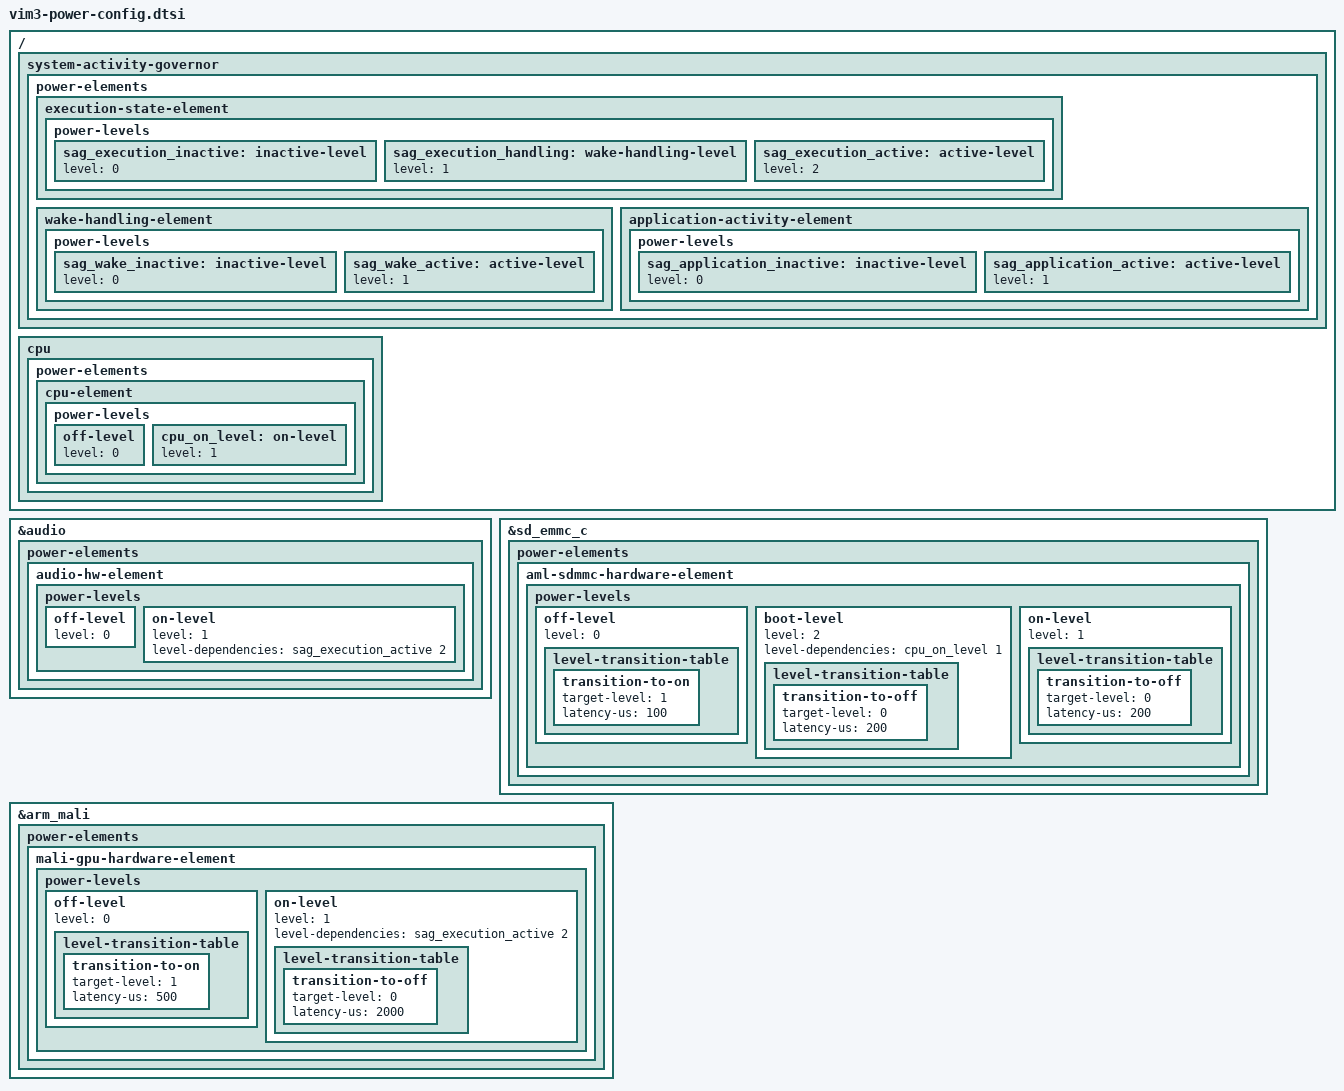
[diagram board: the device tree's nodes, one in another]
// Copyright 2024 The Fuchsia Authors. All rights reserved.
// Use of this source code is governed by a BSD-style license that can be
// found in the LICENSE file.

/dts-v1/;

/include/ "khadas-vim3-board.dtsi"

/ {
	// TODO(https://fxbug.dev/42083285): This has to be kept in sync with
	// sdk/lib/driver/devicetree/visitors/drivers/power/power-element/sag-power-element.yaml and
	// fuchsia.power.system.PowerElements FIDL. For now this needs to be ensured manually.
	// Eventually there will be schema validation and visitor generation based on FIDL.
	system-activity-governor {
		power-elements {
			execution-state-element {
				power-levels {
					sag_execution_inactive: inactive-level {
						level = <0>;
					};
					sag_execution_handling: wake-handling-level {
						level = <1>;
					};
					sag_execution_active: active-level {
						level = <2>;
					};
				};
			};
			wake-handling-element {
				power-levels {
					sag_wake_inactive: inactive-level {
						level = <0>;
					};
					sag_wake_active: active-level {
						level = <1>;
					};
				};
			};
			application-activity-element {
				power-levels {
					sag_application_inactive: inactive-level {
						level = <0>;
					};
					sag_application_active: active-level {
						level = <1>;
					};
				};
			};
		};
	};
	cpu {
		power-elements {
			cpu-element {
				power-levels {
					off-level {
						level = <0>;
					};
					cpu_on_level: on-level {
						level = <1>;
					};
				};
			};
		};
	};
};

&audio {
	power-elements {
		audio-hw-element {
			power-levels {
				off-level {
					level = <0>;
				};
				on-level {
					level = <1>;
					level-dependencies = <&sag_execution_active 2>;
				};
			};
		};
	};
};

&sd_emmc_c {
	power-elements {
		aml-sdmmc-hardware-element {
			power-levels {
				off-level {
					level = <0>;
					level-transition-table {
						transition-to-on {
							target-level = <1>;
							latency-us = <100>;
						};
					};
				};
				boot-level {
					level = <2>;
					level-dependencies = <&cpu_on_level 1>;
					level-transition-table {
						transition-to-off {
							target-level = <0>;
							latency-us = <200>;
						};
					};
        		};
				on-level {
					level = <1>;
					level-transition-table {
						transition-to-off {
							target-level = <0>;
							latency-us = <200>;
						};
					};
				};
			};
		};
	};
};

&arm_mali {
	power-elements {
		mali-gpu-hardware-element {
			power-levels {
				off-level {
					level = <0>;
					level-transition-table {
						transition-to-on {
							target-level = <1>;
							latency-us = <500>;
						};
					};
				};
				on-level {
					level = <1>;
					level-dependencies = <&sag_execution_active 2>;
					level-transition-table {
						transition-to-off {
							target-level = <0>;
							latency-us = <2000>;
						};
					};
				};
			};
		};
	};
};
